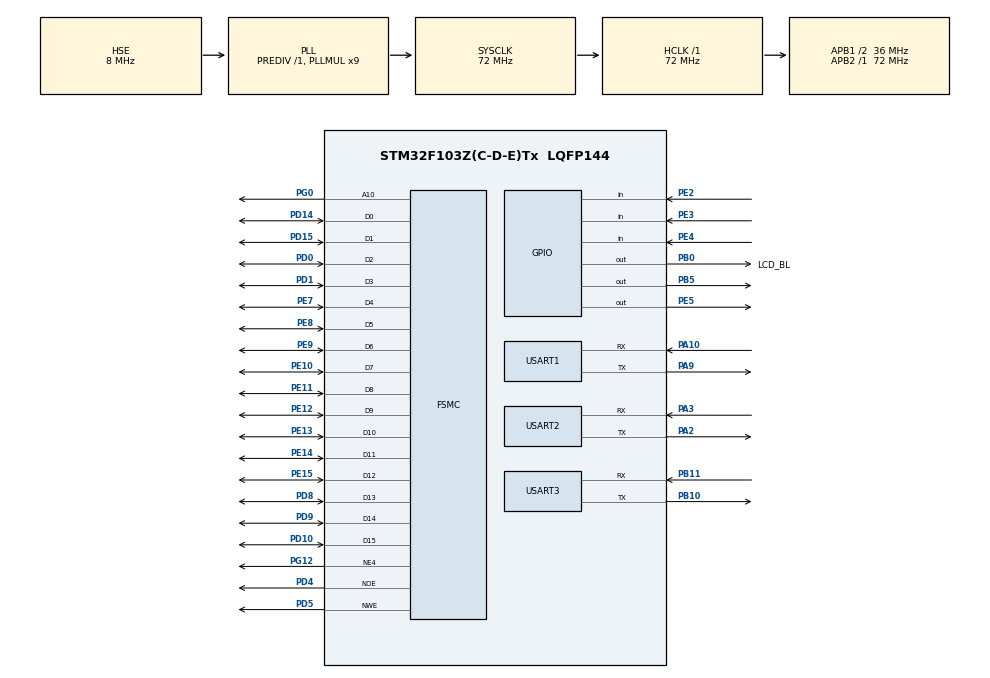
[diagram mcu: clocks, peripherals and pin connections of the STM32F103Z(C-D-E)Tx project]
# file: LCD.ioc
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FREERTOS.Tasks01=Init_Task,2,128,Init_Function,Default,NULL,Dynamic,NULL,NULL;LED_Task,-3,128,LED_Function,Default,NULL,Dynamic,NULL,NULL;LCD_Task,0,128,LCD_Function,Default,NULL,Dynamic,NULL,NULL
FSMC.AddressSetupTime1=0
FSMC.BusTurnAroundDuration1=0
FSMC.DataSetupTime1=26
FSMC.ExtendedAddressSetupTime1=0
FSMC.ExtendedBusTurnAroundDuration1=0
FSMC.ExtendedDataSetupTime1=1
FSMC.ExtendedMode1=FSMC_EXTENDED_MODE_ENABLE
Mcu.Family=STM32F1
Mcu.Name=STM32F103Z(C-D-E)Tx
Mcu.Package=LQFP144
NVIC.PriorityGroup=NVIC_PRIORITYGROUP_4
NVIC.TIM1_UP_IRQn=true\:15\:0\:false\:false\:true\:false\:false\:true
NVIC.TimeBase=TIM1_UP_IRQn
NVIC.TimeBaseIP=TIM1
NVIC.USART1_IRQn=true\:5\:0\:false\:false\:true\:true\:true\:true
NVIC.USART2_IRQn=true\:5\:0\:false\:false\:true\:true\:true\:true
NVIC.USART3_IRQn=true\:5\:0\:false\:false\:true\:true\:true\:true
OSC_IN.Mode=HSE-External-Oscillator
OSC_IN.Signal=RCC_OSC_IN
OSC_OUT.Mode=HSE-External-Oscillator
OSC_OUT.Signal=RCC_OSC_OUT
PA10.Mode=Asynchronous
PA10.Signal=USART1_RX
PA13.Mode=Serial_Wire
PA13.Signal=SYS_JTMS-SWDIO
PA14.Mode=Serial_Wire
PA14.Signal=SYS_JTCK-SWCLK
PA2.Mode=Asynchronous
PA2.Signal=USART2_TX
PA3.Mode=Asynchronous
PA3.Signal=USART2_RX
PA9.Mode=Asynchronous
PA9.Signal=USART1_TX
PB0.GPIO_Label=LCD_BL
PB0.Signal=GPIO_Output
PB10.Mode=Asynchronous
PB10.Signal=USART3_TX
PB11.Mode=Asynchronous
PB11.Signal=USART3_RX
PB5.Signal=GPIO_Output
PD0.Signal=FSMC_D2_DA2
PD1.Signal=FSMC_D3_DA3
PD10.Signal=FSMC_D15_DA15
PD14.Signal=FSMC_D0_DA0
PD15.Signal=FSMC_D1_DA1
PD4.Signal=FSMC_NOE
PD5.Signal=FSMC_NWE
PD8.Signal=FSMC_D13_DA13
PD9.Signal=FSMC_D14_DA14
PE10.Signal=FSMC_D7_DA7
PE11.Signal=FSMC_D8_DA8
PE12.Signal=FSMC_D9_DA9
PE13.Signal=FSMC_D10_DA10
PE14.Signal=FSMC_D11_DA11
PE15.Signal=FSMC_D12_DA12
PE2.GPIO_PuPd=GPIO_PULLUP
PE2.Signal=GPIO_Input
PE3.GPIO_PuPd=GPIO_PULLUP
PE3.Signal=GPIO_Input
PE4.GPIO_PuPd=GPIO_PULLUP
PE4.Signal=GPIO_Input
PE5.Signal=GPIO_Output
PE7.Signal=FSMC_D4_DA4
PE8.Signal=FSMC_D5_DA5
PE9.Signal=FSMC_D6_DA6
PG0.Signal=FSMC_A10
PG12.Mode=NorPsramChipSelect4_1
PG12.Signal=FSMC_NE4
ProjectManager.HeapSize=0x200
ProjectManager.StackSize=0x400
ProjectManager.TargetToolchain=MDK-ARM V5.32
RCC.AHBFreq_Value=72000000
RCC.APB1CLKDivider=RCC_HCLK_DIV2
RCC.APB1Freq_Value=36000000
RCC.APB1TimFreq_Value=72000000
RCC.APB2Freq_Value=72000000
RCC.APB2TimFreq_Value=72000000
RCC.HCLKFreq_Value=72000000
RCC.PLLMUL=RCC_PLL_MUL9
RCC.PLLSourceVirtual=RCC_PLLSOURCE_HSE
RCC.SYSCLKFreq_VALUE=72000000
RCC.SYSCLKSource=RCC_SYSCLKSOURCE_PLLCLK
RCC.USBFreq_Value=72000000
SH.FSMC_A10.0=FSMC_A10,A10_1
SH.FSMC_D0_DA0.0=FSMC_D0,16b-d1
SH.FSMC_D10_DA10.0=FSMC_D10,16b-d1
SH.FSMC_D11_DA11.0=FSMC_D11,16b-d1
SH.FSMC_D12_DA12.0=FSMC_D12,16b-d1
SH.FSMC_D13_DA13.0=FSMC_D13,16b-d1
SH.FSMC_D14_DA14.0=FSMC_D14,16b-d1
SH.FSMC_D15_DA15.0=FSMC_D15,16b-d1
SH.FSMC_D1_DA1.0=FSMC_D1,16b-d1
SH.FSMC_D2_DA2.0=FSMC_D2,16b-d1
SH.FSMC_D3_DA3.0=FSMC_D3,16b-d1
SH.FSMC_D4_DA4.0=FSMC_D4,16b-d1
SH.FSMC_D5_DA5.0=FSMC_D5,16b-d1
SH.FSMC_D6_DA6.0=FSMC_D6,16b-d1
SH.FSMC_D7_DA7.0=FSMC_D7,16b-d1
SH.FSMC_D8_DA8.0=FSMC_D8,16b-d1
SH.FSMC_D9_DA9.0=FSMC_D9,16b-d1
SH.FSMC_NOE.0=FSMC_NOE,Lcd1
SH.FSMC_NWE.0=FSMC_NWE,Lcd1
USART1.VirtualMode=VM_ASYNC
USART2.VirtualMode=VM_ASYNC
USART3.VirtualMode=VM_ASYNC
VP_FREERTOS_VS_CMSIS_V1.Mode=CMSIS_V1
VP_SYS_VS_tim1.Mode=TIM1
board=custom

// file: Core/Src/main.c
/* USER CODE BEGIN Header */
/**
  ******************************************************************************
  * @file           : main.c
  * @brief          : Main program body
  ******************************************************************************
  * @attention
  *
  * Copyright (c) 2023 STMicroelectronics.
  * All rights reserved.
  *
  * This software is licensed under terms that can be found in the LICENSE file
  * in the root directory of this software component.
  * If no LICENSE file comes with this software, it is provided AS-IS.
  *
  ******************************************************************************
  */
/* USER CODE END Header */
#include "main.h"
#include "cmsis_os.h"
#include "usart.h"
#include "gpio.h"
#include "fsmc.h"

void SystemClock_Config(void);
void MX_FREERTOS_Init(void);

int main(void)
{

  /* MCU Configuration--------------------------------------------------------*/

  /* Reset of all peripherals, Initializes the Flash interface and the Systick. */
  HAL_Init();

  /* Configure the system clock */
  SystemClock_Config();

  /* Initialize all configured peripherals */
  MX_GPIO_Init();
  MX_FSMC_Init();
  MX_USART1_UART_Init();
  MX_USART2_UART_Init();
  MX_USART3_UART_Init();
  /* USER CODE BEGIN 2 */

  /* Configure the system clock */
  /* USER CODE END 2 */

  /* Call init function for freertos objects (in freertos.c) */
  MX_FREERTOS_Init();
  /* Start scheduler */
  osKernelStart();

  /* We should never get here as control is now taken by the scheduler */
  /* Infinite loop */
  while (1)
  {

  }
}

void SystemClock_Config(void)
{
  RCC_OscInitTypeDef RCC_OscInitStruct = {0};
  RCC_ClkInitTypeDef RCC_ClkInitStruct = {0};

  /** Initializes the RCC Oscillators according to the specified parameters
  * in the RCC_OscInitTypeDef structure.
  */
  RCC_OscInitStruct.OscillatorType = RCC_OSCILLATORTYPE_HSE;
  RCC_OscInitStruct.HSEState = RCC_HSE_ON;
  RCC_OscInitStruct.HSEPredivValue = RCC_HSE_PREDIV_DIV1;
  RCC_OscInitStruct.HSIState = RCC_HSI_ON;
  RCC_OscInitStruct.PLL.PLLState = RCC_PLL_ON;
  RCC_OscInitStruct.PLL.PLLSource = RCC_PLLSOURCE_HSE;
  RCC_OscInitStruct.PLL.PLLMUL = RCC_PLL_MUL9;
  if (HAL_RCC_OscConfig(&RCC_OscInitStruct) != HAL_OK)
  {
    Error_Handler();
  }
  /** Initializes the CPU, AHB and APB buses clocks
  */
  RCC_ClkInitStruct.ClockType = RCC_CLOCKTYPE_HCLK|RCC_CLOCKTYPE_SYSCLK
                              |RCC_CLOCKTYPE_PCLK1|RCC_CLOCKTYPE_PCLK2;
  RCC_ClkInitStruct.SYSCLKSource = RCC_SYSCLKSOURCE_PLLCLK;
  RCC_ClkInitStruct.AHBCLKDivider = RCC_SYSCLK_DIV1;
  RCC_ClkInitStruct.APB1CLKDivider = RCC_HCLK_DIV2;
  RCC_ClkInitStruct.APB2CLKDivider = RCC_HCLK_DIV1;

  if (HAL_RCC_ClockConfig(&RCC_ClkInitStruct, FLASH_LATENCY_2) != HAL_OK)
  {
    Error_Handler();
  }
}

void HAL_TIM_PeriodElapsedCallback(TIM_HandleTypeDef *htim)
{
  if (htim->Instance == TIM1) {
    HAL_IncTick();
  }
}

void Error_Handler(void)
{
  __disable_irq();
  while (1)
  {
  }
}

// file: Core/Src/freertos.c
/* USER CODE BEGIN Header */
/**
  ******************************************************************************
  * File Name          : freertos.c
  * Description        : Code for freertos applications
  ******************************************************************************
  * @attention
  *
  * Copyright (c) 2023 STMicroelectronics.
  * All rights reserved.
  *
  * This software is licensed under terms that can be found in the LICENSE file
  * in the root directory of this software component.
  * If no LICENSE file comes with this software, it is provided AS-IS.
  *
  ******************************************************************************
  */
/* USER CODE END Header */

#include "FreeRTOS.h"
#include "task.h"
#include "main.h"
#include "cmsis_os.h"

osThreadId Init_TaskHandle;
osThreadId LED_TaskHandle;
osThreadId LCD_TaskHandle;

void Init_Function(void const * argument);
void LED_Function(void const * argument);
void LCD_Function(void const * argument);

void MX_FREERTOS_Init(void); /* (MISRA C 2004 rule 8.1) */

/* GetIdleTaskMemory prototype (linked to static allocation support) */
void vApplicationGetIdleTaskMemory( StaticTask_t **ppxIdleTaskTCBBuffer, StackType_t **ppxIdleTaskStackBuffer, uint32_t *pulIdleTaskStackSize );

/* USER CODE BEGIN GET_IDLE_TASK_MEMORY */
static StaticTask_t xIdleTaskTCBBuffer;
static StackType_t xIdleStack[configMINIMAL_STACK_SIZE];

void vApplicationGetIdleTaskMemory( StaticTask_t **ppxIdleTaskTCBBuffer, StackType_t **ppxIdleTaskStackBuffer, uint32_t *pulIdleTaskStackSize )
{
  *ppxIdleTaskTCBBuffer = &xIdleTaskTCBBuffer;
  *ppxIdleTaskStackBuffer = &xIdleStack[0];
  *pulIdleTaskStackSize = configMINIMAL_STACK_SIZE;
  /* place for user code */
}
/* USER CODE END GET_IDLE_TASK_MEMORY */

void MX_FREERTOS_Init(void) {

  /* Create the thread(s) */
  /* definition and creation of Init_Task */
  osThreadDef(Init_Task, Init_Function, osPriorityHigh, 0, 128);
  Init_TaskHandle = osThreadCreate(osThread(Init_Task), NULL);

  /* definition and creation of LED_Task */
  osThreadDef(LED_Task, LED_Function, osPriorityIdle, 0, 128);
  LED_TaskHandle = osThreadCreate(osThread(LED_Task), NULL);

  /* definition and creation of LCD_Task */
  osThreadDef(LCD_Task, LCD_Function, osPriorityNormal, 0, 128);
  LCD_TaskHandle = osThreadCreate(osThread(LCD_Task), NULL);

}

void Init_Function(void const * argument)
{
  /* USER CODE BEGIN Init_Function */
  /* Infinite loop */
  for(;;)
  {
		TFTLCD_Init();
		LCD_Clear(GREEN);
		LCD_ShowString(30,40,210,24,24,(uint8_t*)"WHAT A DASDA");
		vTaskDelete(NULL);
    osDelay(1);
  }
  /* USER CODE END Init_Function */
}

void LED_Function(void const * argument)
{
  /* USER CODE BEGIN LED_Function */
  /* Infinite loop */
  for(;;)
  {
		HAL_GPIO_TogglePin(LED1_GPIO_Port,LED1_Pin);
    osDelay(500);
  }
  /* USER CODE END LED_Function */
}

void LCD_Function(void const * argument)
{
  for(;;)
  {
    osDelay(1);
  }
}
